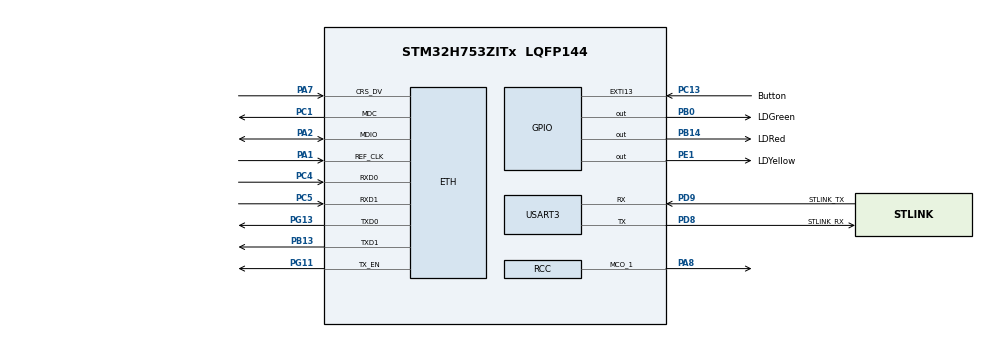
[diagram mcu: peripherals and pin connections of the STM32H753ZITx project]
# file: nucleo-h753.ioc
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CORTEX_M7.AccessPermission_Spec=MPU_REGION_FULL_ACCESS
CORTEX_M7.BaseAddress_Spec=0x30000000
CORTEX_M7.CPU_DCache=Disabled
CORTEX_M7.CPU_ICache=Disabled
CORTEX_M7.MPU_Control=MPU_HFNMI_PRIVDEF_NONE
CORTEX_M7.Size_Spec=MPU_REGION_SIZE_32KB
CORTEX_M7.TypeExtField_Spec=MPU_TEX_LEVEL1
CORTEX_M7.default_mode_Activation=1
ETH.MediaInterface=HAL_ETH_RMII_MODE
HASH.SecureHashAlgorithmType=SHA256
HASH.pKey=__NULL
Mcu.Family=STM32H7
Mcu.Name=STM32H753ZITx
Mcu.Package=LQFP144
NVIC.ETH_IRQn=true\:0\:0\:false\:false\:false\:true\:true\:true
NVIC.EXTI15_10_IRQn=true\:15\:0\:true\:false\:true\:false\:true\:true
NVIC.PriorityGroup=NVIC_PRIORITYGROUP_4
NVIC.TIM6_DAC_IRQn=true\:14\:0\:true\:false\:true\:false\:true\:true
NVIC.TimeBase=TIM6_DAC_IRQn
NVIC.TimeBaseIP=TIM6
PA1.Mode=RMII
PA1.Signal=ETH_REF_CLK
PA2.Mode=RMII
PA2.Signal=ETH_MDIO
PA7.Mode=RMII
PA7.Signal=ETH_CRS_DV
PA8.Mode=Clock-out-1
PA8.Signal=RCC_MCO_1
PB0.GPIO_Label=LDGreen
PB0.Signal=GPIO_Output
PB13.Mode=RMII
PB13.Signal=ETH_TXD1
PB14.GPIO_Label=LDRed
PB14.Signal=GPIO_Output
PC1.Mode=RMII
PC1.Signal=ETH_MDC
PC13.GPIO_Label=Button
PC13.Signal=GPXTI13
PC14-OSC32_IN\ (OSC32_IN).Signal=RCC_OSC32_IN
PC15-OSC32_OUT\ (OSC32_OUT).Signal=RCC_OSC32_OUT
PC4.Mode=RMII
PC4.Signal=ETH_RXD0
PC5.Mode=RMII
PC5.Signal=ETH_RXD1
PD8.GPIO_Label=STLINK_RX
PD8.Mode=Asynchronous
PD8.Signal=USART3_TX
PD9.GPIO_Label=STLINK_TX
PD9.Mode=Asynchronous
PD9.Signal=USART3_RX
PE1.GPIO_Label=LDYellow
PE1.Signal=GPIO_Output
PG11.Mode=RMII
PG11.Signal=ETH_TX_EN
PG13.Mode=RMII
PG13.Signal=ETH_TXD0
PH0-OSC_IN\ (PH0).Mode=HSE-External-Oscillator
PH0-OSC_IN\ (PH0).Signal=RCC_OSC_IN
PH1-OSC_OUT\ (PH1).Mode=HSE-External-Oscillator
PH1-OSC_OUT\ (PH1).Signal=RCC_OSC_OUT
ProjectManager.HeapSize=0x200
ProjectManager.StackSize=0x400
ProjectManager.TargetToolchain=Makefile
RCC.ADCFreq_Value=129000000
RCC.APB1Freq_Value=120000000
RCC.APB2Freq_Value=120000000
RCC.APB3Freq_Value=120000000
RCC.APB4Freq_Value=120000000
RCC.CortexFreq_Value=480000000
RCC.D1PPRE=RCC_APB3_DIV2
RCC.D2PPRE1=RCC_APB1_DIV2
RCC.D2PPRE2=RCC_APB2_DIV2
RCC.D3PPRE=RCC_APB4_DIV2
RCC.DIVM1=4
RCC.DIVN1=60
RCC.DIVQ1=4
RCC.HCLKFreq_Value=240000000
RCC.HPRE=RCC_HCLK_DIV2
RCC.HSE_VALUE=8000000
RCC.PLL2FRACN=0
RCC.PLL3FRACN=0
RCC.PLLFRACN=0
RCC.PWR_Regulator_Voltage_Scale=PWR_REGULATOR_VOLTAGE_SCALE0
RCC.SYSCLKFreq_VALUE=480000000
RCC.SYSCLKSource=RCC_SYSCLKSOURCE_PLLCLK
RCC.USBFreq_Value=240000000
USART3.VirtualMode-Asynchronous=VM_ASYNC
VP_CRYP_VS_CRYP.Mode=CRYP_Activate
VP_HASH_VS_HASH.Mode=HASH_Activate
VP_MEMORYMAP_VS_MEMORYMAP.Mode=CurAppReg
VP_RNG_VS_RNG.Mode=RNG_Activate
VP_SYS_VS_tim6.Mode=TIM6
board=NUCLEO-H753ZI

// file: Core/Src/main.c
/* USER CODE BEGIN Header */
/**
  ******************************************************************************
  * @file           : main.c
  * @brief          : Main program body
  ******************************************************************************
  * @attention
  *
  * Copyright (c) 2025 STMicroelectronics.
  * All rights reserved.
  *
  * This software is licensed under terms that can be found in the LICENSE file
  * in the root directory of this software component.
  * If no LICENSE file comes with this software, it is provided AS-IS.
  *
  ******************************************************************************
  */
/* USER CODE END Header */
#include "main.h"
#include "cryp.h"
#include "eth.h"
#include "hash.h"
#include "rng.h"
#include "usart.h"
#include "gpio.h"

void SystemClock_Config(void);
static void MPU_Config(void);
/* USER CODE BEGIN PFP */
/* External functions from QP/C framework */

/**
  * @brief  Weak application initialization hook
  * @note   Override this function to provide custom initialization
  *         For example, QP/C framework initialization in qpc-adapter.c
  * @retval None
  */
__weak void application_init(void)
{
  /* Default: Do nothing - bare metal application */
  /* Override in downstream project to add RTOS/framework initialization */
}
/* USER CODE END PFP */

int main(void)
{

  /* USER CODE BEGIN 1 */
  /* Paint stack with watermark pattern for usage monitoring */
  /* USER CODE END 1 */

  /* MPU Configuration--------------------------------------------------------*/
  MPU_Config();

  /* MCU Configuration--------------------------------------------------------*/

  /* Reset of all peripherals, Initializes the Flash interface and the Systick. */
  HAL_Init();

  /* Configure the system clock */
  SystemClock_Config();

  /* Initialize all configured peripherals */
  MX_GPIO_Init();
  MX_CRYP_Init();
  MX_HASH_Init();
  MX_RNG_Init();
  MX_ETH_Init();
  MX_USART3_UART_Init();
  /* USER CODE BEGIN 2 */

  /* Initialize QP/C framework and start active objects */
  /* Note: application_init() never returns - QK kernel takes over */
  application_init();

  /* USER CODE END 2 */

  /* Infinite loop */
  /* USER CODE BEGIN WHILE */
  /* NOTE: Code below is unreachable - QK kernel runs in application_init() */
  while (1)
  {
    /* USER CODE END WHILE */

  }
}

void SystemClock_Config(void)
{
  RCC_OscInitTypeDef RCC_OscInitStruct = {0};
  RCC_ClkInitTypeDef RCC_ClkInitStruct = {0};

  /** Supply configuration update enable
  */
  HAL_PWREx_ConfigSupply(PWR_LDO_SUPPLY);

  /** Configure the main internal regulator output voltage
  */
  __HAL_PWR_VOLTAGESCALING_CONFIG(PWR_REGULATOR_VOLTAGE_SCALE0);

  while(!__HAL_PWR_GET_FLAG(PWR_FLAG_VOSRDY)) {}

  /** Initializes the RCC Oscillators according to the specified parameters
  * in the RCC_OscInitTypeDef structure.
  */
  RCC_OscInitStruct.OscillatorType = RCC_OSCILLATORTYPE_HSI48|RCC_OSCILLATORTYPE_HSI;
  RCC_OscInitStruct.HSIState = RCC_HSI_DIV1;
  RCC_OscInitStruct.HSICalibrationValue = RCC_HSICALIBRATION_DEFAULT;
  RCC_OscInitStruct.HSI48State = RCC_HSI48_ON;
  RCC_OscInitStruct.PLL.PLLState = RCC_PLL_ON;
  RCC_OscInitStruct.PLL.PLLSource = RCC_PLLSOURCE_HSI;
  RCC_OscInitStruct.PLL.PLLM = 4;
  RCC_OscInitStruct.PLL.PLLN = 60;
  RCC_OscInitStruct.PLL.PLLP = 2;
  RCC_OscInitStruct.PLL.PLLQ = 4;
  RCC_OscInitStruct.PLL.PLLR = 2;
  RCC_OscInitStruct.PLL.PLLRGE = RCC_PLL1VCIRANGE_3;
  RCC_OscInitStruct.PLL.PLLVCOSEL = RCC_PLL1VCOWIDE;
  RCC_OscInitStruct.PLL.PLLFRACN = 0;
  if (HAL_RCC_OscConfig(&RCC_OscInitStruct) != HAL_OK)
  {
    Error_Handler();
  }

  /** Initializes the CPU, AHB and APB buses clocks
  */
  RCC_ClkInitStruct.ClockType = RCC_CLOCKTYPE_HCLK|RCC_CLOCKTYPE_SYSCLK
                              |RCC_CLOCKTYPE_PCLK1|RCC_CLOCKTYPE_PCLK2
                              |RCC_CLOCKTYPE_D3PCLK1|RCC_CLOCKTYPE_D1PCLK1;
  RCC_ClkInitStruct.SYSCLKSource = RCC_SYSCLKSOURCE_PLLCLK;
  RCC_ClkInitStruct.SYSCLKDivider = RCC_SYSCLK_DIV1;
  RCC_ClkInitStruct.AHBCLKDivider = RCC_HCLK_DIV2;
  RCC_ClkInitStruct.APB3CLKDivider = RCC_APB3_DIV2;
  RCC_ClkInitStruct.APB1CLKDivider = RCC_APB1_DIV2;
  RCC_ClkInitStruct.APB2CLKDivider = RCC_APB2_DIV2;
  RCC_ClkInitStruct.APB4CLKDivider = RCC_APB4_DIV2;

  if (HAL_RCC_ClockConfig(&RCC_ClkInitStruct, FLASH_LATENCY_4) != HAL_OK)
  {
    Error_Handler();
  }
  HAL_RCC_MCOConfig(RCC_MCO1, RCC_MCO1SOURCE_HSI, RCC_MCODIV_1);
}

 /* MPU Configuration */

void MPU_Config(void)
{
  MPU_Region_InitTypeDef MPU_InitStruct = {0};

  /* Disables the MPU */
  HAL_MPU_Disable();

  /** Initializes and configures the Region and the memory to be protected
  */
  MPU_InitStruct.Enable = MPU_REGION_ENABLE;
  MPU_InitStruct.Number = MPU_REGION_NUMBER0;
  MPU_InitStruct.BaseAddress = 0x30000000;
  MPU_InitStruct.Size = MPU_REGION_SIZE_32KB;
  MPU_InitStruct.SubRegionDisable = 0x87;
  MPU_InitStruct.TypeExtField = MPU_TEX_LEVEL1;
  MPU_InitStruct.AccessPermission = MPU_REGION_FULL_ACCESS;
  MPU_InitStruct.DisableExec = MPU_INSTRUCTION_ACCESS_DISABLE;
  MPU_InitStruct.IsShareable = MPU_ACCESS_SHAREABLE;
  MPU_InitStruct.IsCacheable = MPU_ACCESS_NOT_CACHEABLE;
  MPU_InitStruct.IsBufferable = MPU_ACCESS_NOT_BUFFERABLE;

  HAL_MPU_ConfigRegion(&MPU_InitStruct);
  /* Enables the MPU */
  HAL_MPU_Enable(MPU_HFNMI_PRIVDEF_NONE);

}

void HAL_TIM_PeriodElapsedCallback(TIM_HandleTypeDef *htim)
{
  if (htim->Instance == TIM6)
  {
    HAL_IncTick();
  }
}

void Error_Handler(void)
{
  __disable_irq();
  while (1)
  {
  }
}
